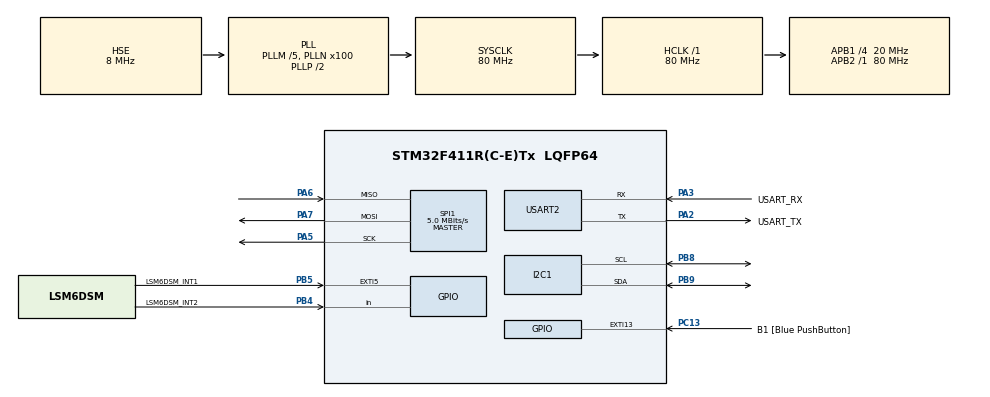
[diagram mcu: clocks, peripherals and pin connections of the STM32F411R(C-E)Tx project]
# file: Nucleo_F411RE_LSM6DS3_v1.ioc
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Mcu.Family=STM32F4
RCC.PLLSourceVirtual=RCC_PLLSOURCE_HSE
PA6.Mode=Full_Duplex_Master
RCC.CortexFreq_Value=80000000
PA7.Mode=Full_Duplex_Master
SPI1.VirtualType=VM_MASTER
I2C1.GeneralCallMode=I2C_GENERALCALL_DISABLE
PC13-ANTI_TAMP.GPIO_Label=B1 [Blue PushButton]
PA14.GPIO_Label=TCK
PH1\ -\ OSC_OUT.Mode=HSE-External-Oscillator
RCC.APB1CLKDivider=RCC_HCLK_DIV4
PC14-OSC32_IN.Signal=RCC_OSC32_IN
NVIC.USART2_IRQn=true\:0\:0\:false\:true\:true\:1\:true\:true
RCC.SYSCLKSource=RCC_SYSCLKSOURCE_PLLCLK
ProjectManager.StackSize=0x400
PA3.Mode=Asynchronous
PA13.Signal=SYS_JTMS-SWDIO
PH0\ -\ OSC_IN.Mode=HSE-External-Oscillator
PH0\ -\ OSC_IN.Signal=RCC_OSC_IN
ProjectManager.TargetToolchain=STM32CubeIDE
I2C1.I2C_Mode=I2C_Standard
SPI1.Direction=SPI_DIRECTION_2LINES
RCC.HCLKFreq_Value=80000000
PB9.Mode=I2C
RCC.APB2TimFreq_Value=80000000
SPI1.CalculateBaudRate=5.0 MBits/s
RCC.LSE_VALUE=32768
PC15-OSC32_OUT.Signal=RCC_OSC32_OUT
RCC.AHBFreq_Value=80000000
PA5.Signal=SPI1_SCK
RCC.HSE_VALUE=8000000
PH1\ -\ OSC_OUT.Signal=RCC_OSC_OUT
board=NUCLEO-F411RE
PC13-ANTI_TAMP.Signal=GPXTI13
RCC.VCOOutputFreq_Value=160000000
RCC.APB2Freq_Value=80000000
I2C1.NoStretchMode=I2C_NOSTRETCH_DISABLE
PB4.GPIO_Label=LSM6DSM_INT2
SPI1.Mode=SPI_MODE_MASTER
Mcu.Name=STM32F411R(C-E)Tx
PA2.Signal=USART2_TX
PA13.GPIO_Label=TMS
RCC.FLatency-AdvancedSettings=FLASH_LATENCY_2
I2C1.OwnAddress=0x6B
RCC.48MHZClocksFreq_Value=40000000
PB3.Signal=SYS_JTDO-SWO
RCC.SYSCLKFreq_VALUE=80000000
Mcu.Package=LQFP64
PB5.Signal=GPXTI5
PB9.Signal=I2C1_SDA
PA6.Signal=SPI1_MISO
USART2.VirtualMode=VM_ASYNC
PC13-ANTI_TAMP.GPIO_ModeDefaultEXTI=GPIO_MODE_EVT_RISING
PA2.GPIO_Label=USART_TX
NVIC.EXTI9_5_IRQn=true\:0\:0\:false\:false\:true\:true\:true
PA14.Signal=SYS_JTCK-SWCLK
ProjectManager.HeapSize=0x200
RCC.HSI_VALUE=16000000
NVIC.PriorityGroup=NVIC_PRIORITYGROUP_0
PB5.GPIO_Label=LSM6DSM_INT1
RCC.PLLM=5
PB8.Mode=I2C
RCC.PLLN=100
RCC.APB1TimFreq_Value=40000000
PA2.Mode=Asynchronous
PB8.Signal=I2C1_SCL
RCC.APB1Freq_Value=20000000
SPI1.BaudRatePrescaler=SPI_BAUDRATEPRESCALER_16
PB4.Signal=GPIO_Input
PA3.GPIO_Label=USART_RX
PA3.Signal=USART2_RX
PA5.Mode=Full_Duplex_Master
PA7.Signal=SPI1_MOSI

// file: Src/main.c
/* USER CODE BEGIN Header */
/**
  ******************************************************************************
  * @file           : main.c
  * @brief          : Main program body
  ******************************************************************************
  * @attention
  *
  * <h2><center>&copy; Copyright (c) 2020 STMicroelectronics.
  * All rights reserved.</center></h2>
  *
  * This software component is licensed by ST under BSD 3-Clause license,
  * the "License"; You may not use this file except in compliance with the
  * License. You may obtain a copy of the License at:
  *                        opensource.org/licenses/BSD-3-Clause
  *
  ******************************************************************************
  */
/* USER CODE END Header */
#include "main.h"
#include "i2c.h"
#include "spi.h"
#include "usart.h"
#include "gpio.h"

/* USER CODE BEGIN Includes */

#include <stdio.h>
#include <stdlib.h>
#include <string.h>

/* USER CODE END Includes */

void SystemClock_Config(void);
static void MX_NVIC_Init(void);
/* USER CODE BEGIN PFP */

void example_main_orientation_6D_lsm6ds3(void);
void example_main_lsm6ds3(void);

/* USER CODE END PFP */

/* USER CODE BEGIN 0 */

// printf under freeRTOS
// https://github.com/leech001/STM32-FreeRTOS-float

//1. Remove the heap_4.c file from the
//\Middlewares\Third_Party\FreeRTOS\Source\portable\MemMang\ directory of your project
//2. Copy the heap_useNewlib.c file from the given repository (src) to the above directory;
//3. Open the FreeRTOS configuration file (FreeRTOSConfig.h) and add an additional define to the section;

// /* USER CODE BEGIN Defines */
// /* Section where parameter definitions can be added (for instance, to override default ones in FreeRTOS.h) */
// #define configUSE_NEWLIB_REENTRANT 1
// /* USER CODE END Defines */
#define PRINTF

int _write(int file, char *ptr, int len)
{
  HAL_UART_Transmit(&huart2,(uint8_t *)ptr,len,10);
  return len;
}

void HAL_GPIO_WRITE_ODR(GPIO_TypeDef* GPIOx, uint16_t GPIO_Pin)
{
  /* Check the parameters */
  assert_param(IS_GPIO_PIN(GPIO_Pin));

  GPIOx->ODR |= GPIO_Pin;
}

/* USER CODE END 0 */

int main(void)
{

  /* MCU Configuration--------------------------------------------------------*/

  /* Reset of all peripherals, Initializes the Flash interface and the Systick. */
  HAL_Init();

  /* Configure the system clock */
  SystemClock_Config();

  /* Initialize all configured peripherals */
  MX_GPIO_Init();
  MX_USART2_UART_Init();
  MX_I2C1_Init();
  MX_SPI1_Init();

  /* Initialize interrupts */
  MX_NVIC_Init();
  /* USER CODE BEGIN 2 */

 //  example_main_orientation_6D_lsm6ds3();
   example_main_lsm6ds3();

  /* USER CODE END 2 */

  /* Infinite loop */
  while (1)
  {

  }
}

void SystemClock_Config(void)
{
  RCC_OscInitTypeDef RCC_OscInitStruct = {0};
  RCC_ClkInitTypeDef RCC_ClkInitStruct = {0};

  /** Configure the main internal regulator output voltage
  */
  __HAL_RCC_PWR_CLK_ENABLE();
  __HAL_PWR_VOLTAGESCALING_CONFIG(PWR_REGULATOR_VOLTAGE_SCALE1);
  /** Initializes the RCC Oscillators according to the specified parameters
  * in the RCC_OscInitTypeDef structure.
  */
  RCC_OscInitStruct.OscillatorType = RCC_OSCILLATORTYPE_HSE;
  RCC_OscInitStruct.HSEState = RCC_HSE_ON;
  RCC_OscInitStruct.PLL.PLLState = RCC_PLL_ON;
  RCC_OscInitStruct.PLL.PLLSource = RCC_PLLSOURCE_HSE;
  RCC_OscInitStruct.PLL.PLLM = 5;
  RCC_OscInitStruct.PLL.PLLN = 100;
  RCC_OscInitStruct.PLL.PLLP = RCC_PLLP_DIV2;
  RCC_OscInitStruct.PLL.PLLQ = 4;
  if (HAL_RCC_OscConfig(&RCC_OscInitStruct) != HAL_OK)
  {
    Error_Handler();
  }
  /** Initializes the CPU, AHB and APB buses clocks
  */
  RCC_ClkInitStruct.ClockType = RCC_CLOCKTYPE_HCLK|RCC_CLOCKTYPE_SYSCLK
                              |RCC_CLOCKTYPE_PCLK1|RCC_CLOCKTYPE_PCLK2;
  RCC_ClkInitStruct.SYSCLKSource = RCC_SYSCLKSOURCE_PLLCLK;
  RCC_ClkInitStruct.AHBCLKDivider = RCC_SYSCLK_DIV1;
  RCC_ClkInitStruct.APB1CLKDivider = RCC_HCLK_DIV4;
  RCC_ClkInitStruct.APB2CLKDivider = RCC_HCLK_DIV1;

  if (HAL_RCC_ClockConfig(&RCC_ClkInitStruct, FLASH_LATENCY_2) != HAL_OK)
  {
    Error_Handler();
  }
}

/**
  * @brief NVIC Configuration.
  * @retval None
  */
static void MX_NVIC_Init(void)
{
  /* USART2_IRQn interrupt configuration */
  HAL_NVIC_SetPriority(USART2_IRQn, 0, 0);
  HAL_NVIC_EnableIRQ(USART2_IRQn);
}

void Error_Handler(void)
{
}

/************************ (C) COPYRIGHT STMicroelectronics *****END OF FILE****/
